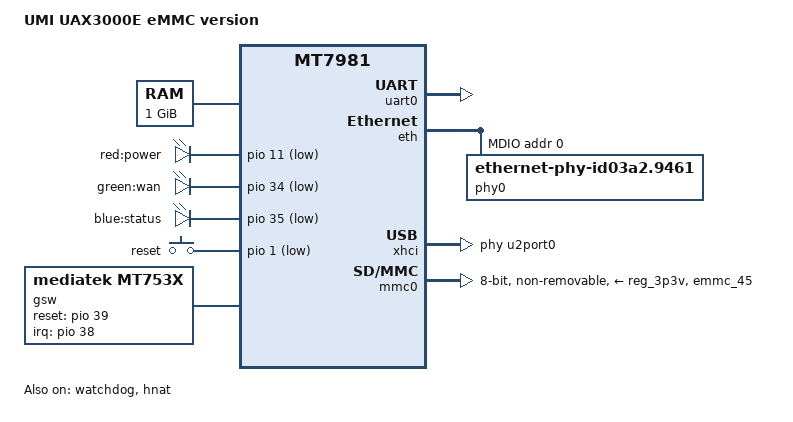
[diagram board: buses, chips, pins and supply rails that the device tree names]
/dts-v1/;
#include "mt7981.dtsi"

/ {
	model = "UMI UAX3000E eMMC version";
	compatible = "umi,uax3000e", "mediatek,mt7981";

	chosen {
		bootargs = "console=ttyS0,115200n1 loglevel=8 \
			    earlycon=uart8250,mmio32,0x11002000 \
			    root=PARTLABEL=rootfs rootwait rootfstype=squashfs,f2fs";
	};

	aliases {
		led-boot = &red_led;
		led-failsafe = &red_led;
		led-running = &green:wan;
		led-upgrade = &blue_led;
	};

	memory {
		reg = <0 0x40000000 0 0x40000000>;
	};

        gpio-leds {
                compatible = "gpio-leds";

                red_led: led-0 {
                        label = "red:power";
                        gpios = <&pio 11 GPIO_ACTIVE_LOW>;
                };

                green_led: led-1 {
                        label = "green:wan";
                        gpios = <&pio 34 GPIO_ACTIVE_LOW>;
                };
                
		blue_led: led-2 {
			label = "blue:status";
			gpios = <&pio 35 GPIO_ACTIVE_LOW>;
		};
	};

	gpio-keys {
		compatible = "gpio-keys";
		reset {
			label = "reset";
			linux,code = <KEY_RESTART>;
			gpios = <&pio 1 GPIO_ACTIVE_LOW>;
		};
	};

	gsw: gsw@0 {
		compatible = "mediatek,mt753x";
		mediatek,ethsys = <&ethsys>;
		#address-cells = <1>;
		#size-cells = <0>;
	};
};

&uart0 {
	status = "okay";
};

&watchdog {
	status = "okay";
};

&eth {
	status = "okay";

	gmac0: mac@0 {
		compatible = "mediatek,eth-mac";
		reg = <0>;
		phy-mode = "2500base-x";

		fixed-link {
			speed = <2500>;
			full-duplex;
			pause;
		};
	};

	gmac1: mac@1 {
		compatible = "mediatek,eth-mac";
		reg = <1>;
		phy-mode = "gmii";
		phy-handle = <&phy0>;
	};

	mdio: mdio-bus {
		#address-cells = <1>;
		#size-cells = <0>;

		phy0: ethernet-phy@0 {
			compatible = "ethernet-phy-id03a2.9461";
			reg = <0>;
			phy-mode = "gmii";
			nvmem-cells = <&phy_calibration>;
			nvmem-cell-names = "phy-cal-data";
		};
	};
};

&gsw {
	mediatek,mdio = <&mdio>;
	mediatek,mdio_master_pinmux = <0>;
	reset-gpios = <&pio 39 0>;
	interrupt-parent = <&pio>;
	interrupts = <38 IRQ_TYPE_LEVEL_HIGH>;
	status = "okay";

	port6: port@6 {
		compatible = "mediatek,mt753x-port";
		mediatek,ssc-on;
		reg = <6>;
		phy-mode = "sgmii";

		fixed-link {
			speed = <2500>;
			full-duplex;
		};
	};
};

&hnat {
	mtketh-wan = "eth1";
	mtketh-lan = "eth0";
	mtketh-max-gmac = <2>;
	ext-devices-prefix = "usb", "wwan";
	status = "okay";
};

&xhci {
	mediatek,u3p-dis-msk = <0x0>;
	phys = <&u2port0 PHY_TYPE_USB2>,
		   <&u3port0 PHY_TYPE_USB3>;
	status = "okay";
};

&mmc0 {
	bus-width = <8>;
	cap-mmc-highspeed;
	max-frequency = <52000000>;
	no-sd;
	no-sdio;
	non-removable;
	pinctrl-names = "default", "state_uhs";
	pinctrl-0 = <&mmc0_pins_default>;
	pinctrl-1 = <&mmc0_pins_uhs>;
	vmmc-supply = <&reg_3p3v>;
	non-removable;
	status = "okay";
};

&pio {
	mmc0_pins_default: mmc0-pins-default {
		mux {
			function = "flash";
			groups = "emmc_45";
		};
	};

	mmc0_pins_uhs: mmc0-pins-uhs {
		mux {
			function = "flash";
			groups = "emmc_45";
		};
	};
};
